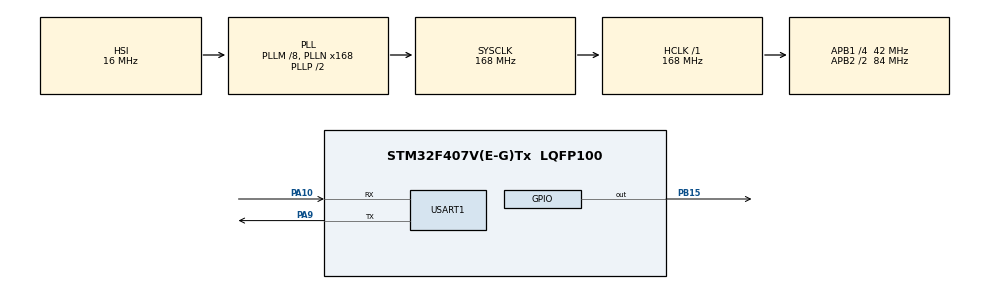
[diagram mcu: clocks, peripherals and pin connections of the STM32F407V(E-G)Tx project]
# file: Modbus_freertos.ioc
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FREERTOS.Tasks01=defaultTask,0,128,StartDefaultTask,Default,NULL,Dynamic,NULL,NULL
Mcu.Family=STM32F4
Mcu.Name=STM32F407V(E-G)Tx
Mcu.Package=LQFP100
NVIC.PriorityGroup=NVIC_PRIORITYGROUP_4
NVIC.TIM6_DAC_IRQn=true\:0\:0\:false\:false\:true\:false\:false\:true
NVIC.TIM7_IRQn=true\:6\:0\:true\:false\:true\:true\:true\:true
NVIC.TimeBase=TIM6_DAC_IRQn
NVIC.TimeBaseIP=TIM6
NVIC.USART1_IRQn=true\:6\:0\:true\:false\:true\:true\:true\:true
PA10.Mode=Asynchronous
PA10.Signal=USART1_RX
PA9.Mode=Asynchronous
PA9.Signal=USART1_TX
PB15.PinState=GPIO_PIN_SET
PB15.Signal=GPIO_Output
ProjectManager.HeapSize=0x200
ProjectManager.StackSize=0x400
ProjectManager.TargetToolchain=MDK-ARM V5
RCC.48MHZClocksFreq_Value=84000000
RCC.AHBFreq_Value=168000000
RCC.APB1CLKDivider=RCC_HCLK_DIV4
RCC.APB1Freq_Value=42000000
RCC.APB1TimFreq_Value=84000000
RCC.APB2CLKDivider=RCC_HCLK_DIV2
RCC.APB2Freq_Value=84000000
RCC.APB2TimFreq_Value=168000000
RCC.CortexFreq_Value=168000000
RCC.HCLKFreq_Value=168000000
RCC.HSE_VALUE=25000000
RCC.HSI_VALUE=16000000
RCC.LSE_VALUE=32768
RCC.PLLM=8
RCC.PLLN=168
RCC.SYSCLKFreq_VALUE=168000000
RCC.SYSCLKSource=RCC_SYSCLKSOURCE_PLLCLK
RCC.VCOOutputFreq_Value=336000000
TIM7.Prescaler=83
TIM7.TIM_MasterOutputTrigger=TIM_TRGO_UPDATE
USART1.StopBits=STOPBITS_2
USART1.VirtualMode=VM_ASYNC
VP_FREERTOS_VS_CMSIS_V1.Mode=CMSIS_V1
VP_SYS_VS_tim6.Mode=TIM6
VP_TIM7_VS_ClockSourceINT.Mode=Enable_Timer
board=custom

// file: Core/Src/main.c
/* USER CODE BEGIN Header */
/**
  ******************************************************************************
  * @file           : main.c
  * @brief          : Main program body
  ******************************************************************************
  * @attention
  *
  * <h2><center>&copy; Copyright (c) 2026 STMicroelectronics.
  * All rights reserved.</center></h2>
  *
  * This software component is licensed by ST under BSD 3-Clause license,
  * the "License"; You may not use this file except in compliance with the
  * License. You may obtain a copy of the License at:
  *                        opensource.org/licenses/BSD-3-Clause
  *
  ******************************************************************************
  */
/* USER CODE END Header */
#include "main.h"
#include "cmsis_os.h"
#include "tim.h"
#include "usart.h"
#include "gpio.h"

/* USER CODE BEGIN Includes */
#include "Modbus_Rtu.h"
/* USER CODE END Includes */

void SystemClock_Config(void);
void MX_FREERTOS_Init(void);

/* USER CODE BEGIN 0 */
Modbus_RTU* mosbus_dev=NULL;
void Modbus_Test(void* arg)
{
	mosbus_dev=&modbus_rtu_dev1;
	mosbus_dev->Init(mosbus_dev,0x01,"uart1_it");
	while(1)
	{
		mosbus_dev->Receive(mosbus_dev);
	}
}
void App_ControlTask(void* arg)
{
	while(1)
	{
		HAL_GPIO_WritePin(GPIOB,GPIO_PIN_15,buf_registers[0]);
		vTaskDelay(50);
	}
}
//SysTick_Handler
/* USER CODE END 0 */

int main(void)
{

  /* MCU Configuration--------------------------------------------------------*/

  /* Reset of all peripherals, Initializes the Flash interface and the Systick. */
  HAL_Init();

  /* Configure the system clock */
  SystemClock_Config();

  /* Initialize all configured peripherals */
  MX_GPIO_Init();
  MX_USART1_UART_Init();
  MX_TIM7_Init();
  /* USER CODE BEGIN 2 */
  TaskHandle_t g_ModbusHandle_t;
  TaskHandle_t g_ControlHandle_t;
	xTaskCreate(Modbus_Test,"modbus",256,NULL,2,&g_ModbusHandle_t);
	xTaskCreate(App_ControlTask,"Control",128,NULL,1,&g_ControlHandle_t);
  /* USER CODE END 2 */

  /* Call init function for freertos objects (in freertos.c) */
  MX_FREERTOS_Init();
  /* Start scheduler */
  osKernelStart();

  /* We should never get here as control is now taken by the scheduler */
  /* Infinite loop */
  while (1)
  {

  }
}

void SystemClock_Config(void)
{
  RCC_OscInitTypeDef RCC_OscInitStruct = {0};
  RCC_ClkInitTypeDef RCC_ClkInitStruct = {0};

  /** Configure the main internal regulator output voltage
  */
  __HAL_RCC_PWR_CLK_ENABLE();
  __HAL_PWR_VOLTAGESCALING_CONFIG(PWR_REGULATOR_VOLTAGE_SCALE1);
  /** Initializes the RCC Oscillators according to the specified parameters
  * in the RCC_OscInitTypeDef structure.
  */
  RCC_OscInitStruct.OscillatorType = RCC_OSCILLATORTYPE_HSI;
  RCC_OscInitStruct.HSIState = RCC_HSI_ON;
  RCC_OscInitStruct.HSICalibrationValue = RCC_HSICALIBRATION_DEFAULT;
  RCC_OscInitStruct.PLL.PLLState = RCC_PLL_ON;
  RCC_OscInitStruct.PLL.PLLSource = RCC_PLLSOURCE_HSI;
  RCC_OscInitStruct.PLL.PLLM = 8;
  RCC_OscInitStruct.PLL.PLLN = 168;
  RCC_OscInitStruct.PLL.PLLP = RCC_PLLP_DIV2;
  RCC_OscInitStruct.PLL.PLLQ = 4;
  if (HAL_RCC_OscConfig(&RCC_OscInitStruct) != HAL_OK)
  {
    Error_Handler();
  }
  /** Initializes the CPU, AHB and APB buses clocks
  */
  RCC_ClkInitStruct.ClockType = RCC_CLOCKTYPE_HCLK|RCC_CLOCKTYPE_SYSCLK
                              |RCC_CLOCKTYPE_PCLK1|RCC_CLOCKTYPE_PCLK2;
  RCC_ClkInitStruct.SYSCLKSource = RCC_SYSCLKSOURCE_PLLCLK;
  RCC_ClkInitStruct.AHBCLKDivider = RCC_SYSCLK_DIV1;
  RCC_ClkInitStruct.APB1CLKDivider = RCC_HCLK_DIV4;
  RCC_ClkInitStruct.APB2CLKDivider = RCC_HCLK_DIV2;

  if (HAL_RCC_ClockConfig(&RCC_ClkInitStruct, FLASH_LATENCY_5) != HAL_OK)
  {
    Error_Handler();
  }
}

 /**
  * @brief  Period elapsed callback in non blocking mode
  * @note   This function is called  when TIM6 interrupt took place, inside
  * HAL_TIM_IRQHandler(). It makes a direct call to HAL_IncTick() to increment
  * a global variable "uwTick" used as application time base.
  * @param  htim : TIM handle
  * @retval None
//  */
//void HAL_TIM_PeriodElapsedCallback(TIM_HandleTypeDef *htim)
//{
//  /* USER CODE BEGIN Callback 0 */

//  /* USER CODE END Callback 0 */
//  if (htim->Instance == TIM6) {
//    HAL_IncTick();
//  }
//  /* USER CODE BEGIN Callback 1 */

//  /* USER CODE END Callback 1 */
//}

void Error_Handler(void)
{
  __disable_irq();
  while (1)
  {
  }
}

/************************ (C) COPYRIGHT STMicroelectronics *****END OF FILE****/

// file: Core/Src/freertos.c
/* USER CODE BEGIN Header */
/**
  ******************************************************************************
  * File Name          : freertos.c
  * Description        : Code for freertos applications
  ******************************************************************************
  * @attention
  *
  * <h2><center>&copy; Copyright (c) 2026 STMicroelectronics.
  * All rights reserved.</center></h2>
  *
  * This software component is licensed by ST under Ultimate Liberty license
  * SLA0044, the "License"; You may not use this file except in compliance with
  * the License. You may obtain a copy of the License at:
  *                             www.st.com/SLA0044
  *
  ******************************************************************************
  */
/* USER CODE END Header */

#include "FreeRTOS.h"
#include "task.h"
#include "main.h"
#include "cmsis_os.h"

osThreadId defaultTaskHandle;

void StartDefaultTask(void const * argument);

void MX_FREERTOS_Init(void); /* (MISRA C 2004 rule 8.1) */

/* GetIdleTaskMemory prototype (linked to static allocation support) */
void vApplicationGetIdleTaskMemory( StaticTask_t **ppxIdleTaskTCBBuffer, StackType_t **ppxIdleTaskStackBuffer, uint32_t *pulIdleTaskStackSize );

/* USER CODE BEGIN GET_IDLE_TASK_MEMORY */
static StaticTask_t xIdleTaskTCBBuffer;
static StackType_t xIdleStack[configMINIMAL_STACK_SIZE];

void vApplicationGetIdleTaskMemory( StaticTask_t **ppxIdleTaskTCBBuffer, StackType_t **ppxIdleTaskStackBuffer, uint32_t *pulIdleTaskStackSize )
{
  *ppxIdleTaskTCBBuffer = &xIdleTaskTCBBuffer;
  *ppxIdleTaskStackBuffer = &xIdleStack[0];
  *pulIdleTaskStackSize = configMINIMAL_STACK_SIZE;
  /* place for user code */
}
/* USER CODE END GET_IDLE_TASK_MEMORY */

void MX_FREERTOS_Init(void) {

  /* Create the thread(s) */
  /* definition and creation of defaultTask */
  osThreadDef(defaultTask, StartDefaultTask, osPriorityNormal, 0, 128);
  defaultTaskHandle = osThreadCreate(osThread(defaultTask), NULL);

}

void StartDefaultTask(void const * argument)
{
  for(;;)
  {
    osDelay(1);
  }
}

/************************ (C) COPYRIGHT STMicroelectronics *****END OF FILE****/
